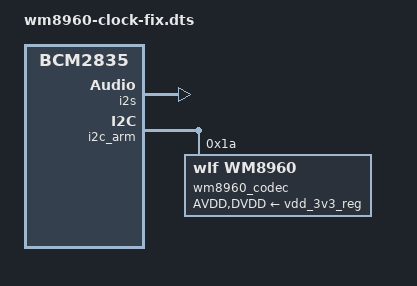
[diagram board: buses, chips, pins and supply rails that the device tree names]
/dts-v1/;
/plugin/;

/ {
    compatible = "brcm,bcm2835";

    fragment@0 {
        target = <&i2s>;
        __overlay__ { status = "okay"; };
    };

    fragment@1 {
        target = <&i2c_arm>;
        __overlay__ {
            #address-cells = <1>;
            #size-cells = <0>;
            status = "okay";
            wm8960_codec: wm8960@1a {
                compatible = "wlf,wm8960";
                reg = <0x1a>;
                #sound-dai-cells = <0>;
                AVDD-supply = <&vdd_3v3_reg>;
                DVDD-supply = <&vdd_3v3_reg>;
                status = "okay";
            };
        };
    };

    fragment@2 {
        target-path = "/";
        __overlay__ {
            wm8960_card: wm8960-soundcard {
                compatible = "simple-audio-card";
                simple-audio-card,name = "wm8960-soundcard";
                simple-audio-card,format = "i2s";
                
                /* Pi liefert Bitclock und Frame-Sync */
                simple-audio-card,bitclock-master = <&dailink0_cpu>;
                simple-audio-card,frame-master = <&dailink0_cpu>;

                simple-audio-card,mclk-fs = <256>;

                dailink0_cpu: simple-audio-card,cpu {
                    sound-dai = <&i2s>;
                };
                dailink0_codec: simple-audio-card,codec {
                    sound-dai = <&wm8960_codec>;
                };
            };
        };
    };
};
